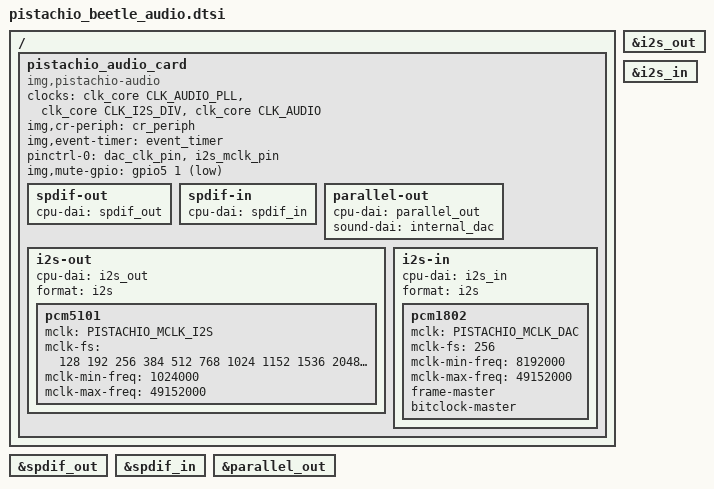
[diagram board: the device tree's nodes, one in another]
/*
 * Copyright (C) 2015 Imagination Technologies Ltd.
 *
 * This program is free software; you can redistribute it and/or modify
 * it under the terms of the GNU General Public License version 2 as
 * published by the Free Software Foundation.
 */

#include "pistachio.dtsi"
#include <dt-bindings/sound/pistachio-audio.h>

/ {
	pistachio_audio_card {
		compatible = "img,pistachio-audio";

		clocks = <&clk_core CLK_AUDIO_PLL>,
			 <&clk_core CLK_I2S_DIV>,
			 <&clk_core CLK_AUDIO>;
		clock-names = "audio_pll", "i2s_mclk", "dac_clk";

		img,cr-periph = <&cr_periph>;
		img,event-timer = <&event_timer>;

		pinctrl-names = "default";
		pinctrl-0 = <&dac_clk_pin>, <&i2s_mclk_pin>;

		img,mute-gpio = <&gpio5 1 GPIO_ACTIVE_LOW>;

		spdif-out {
			cpu-dai = <&spdif_out>;
		};

		spdif-in {
			cpu-dai = <&spdif_in>;
		};

		parallel-out {
			cpu-dai = <&parallel_out>;
			sound-dai = <&internal_dac>;
		};

		i2s-out {
			cpu-dai = <&i2s_out>;
			format = "i2s";

			pcm5101 {
				mclk = <PISTACHIO_MCLK_I2S>;
				mclk-fs = <128 192 256 384 512 768 1024 1152 1536 2048 3072>;
				mclk-min-freq = <1024000>;
				mclk-max-freq = <49152000>;
			};
		};

		i2s-in {
			cpu-dai = <&i2s_in>;
			format = "i2s";

			pcm1802 {
				mclk = <PISTACHIO_MCLK_DAC>;
				mclk-fs = <256>;
				mclk-min-freq = <8192000>;
				mclk-max-freq = <49152000>;
				frame-master;
				bitclock-master;
			};
		};
	};
};

&i2s_out {
	status = "okay";
};

&i2s_in {
	status = "okay";
};

&spdif_out {
	status = "okay";
};

&spdif_in {
	status = "okay";
};

&parallel_out {
	status = "okay";
};
